# NAVSS0_MODSS_INTA_1_MODSS_INTA1_CFG_IMAP register map
Vendor: Texas Instruments
Peripheral module from a debugger description file (folder J721S2).
Registers are 64-bit, read-write, reset 0x0 unless marked. A register's access mark holds for its fields unless they carry their own. Offsets are as the file gives them; lines under a group give offsets from that group; [hi:lo] are bit positions; {n}, {i} and the like mark numbered series; 'fields as' and 'values as' point back to an identical list; <NAME> marks a mode.

## NAVSS0_MODSS_INTA_1_MODSS_INTA1_CFG_IMAP
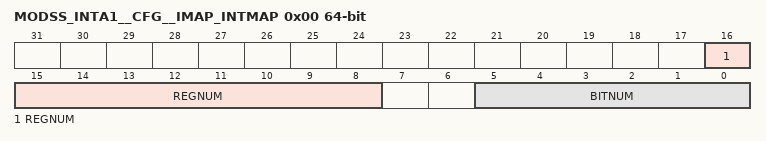
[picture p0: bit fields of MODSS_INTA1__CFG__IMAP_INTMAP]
0x00 MODSS_INTA1__CFG__IMAP_INTMAP — The Interrupt Mapping Register controls which of N virtual interrupt source outputs this channels physical interrupt sources will map onto.
  [16:8] REGNUM — Virtual interrupt status register number: this field specifies which of the potential virtual interrupt cause registers the event pending bit will appear in.
  [5:0] BITNUM — Virtual interrupt cause register bit number: this field specifies which of the 64 bits in the specified virtual interrupt cause register the event pending bit will appear in.
